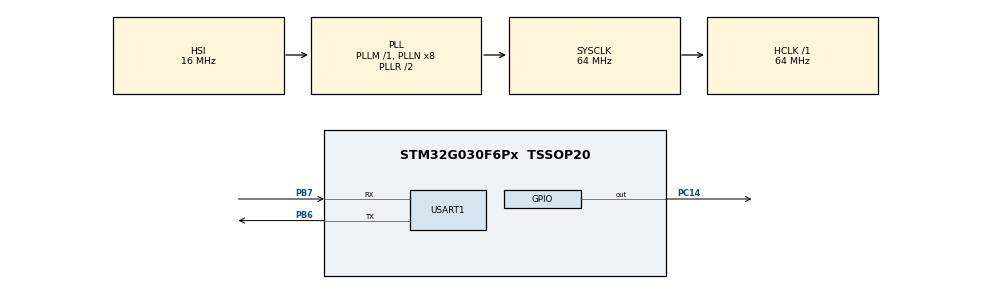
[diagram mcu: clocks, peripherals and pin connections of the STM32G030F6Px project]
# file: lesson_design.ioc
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Dma.Request0=USART1_TX
Dma.Request1=USART1_RX
Dma.USART1_RX.1.Direction=DMA_PERIPH_TO_MEMORY
Dma.USART1_RX.1.EventEnable=DISABLE
Dma.USART1_RX.1.Instance=DMA1_Channel2
Dma.USART1_RX.1.MemDataAlignment=DMA_MDATAALIGN_BYTE
Dma.USART1_RX.1.MemInc=DMA_MINC_ENABLE
Dma.USART1_RX.1.Mode=DMA_NORMAL
Dma.USART1_RX.1.PeriphDataAlignment=DMA_PDATAALIGN_BYTE
Dma.USART1_RX.1.PeriphInc=DMA_PINC_DISABLE
Dma.USART1_RX.1.Polarity=HAL_DMAMUX_REQ_GEN_RISING
Dma.USART1_RX.1.Priority=DMA_PRIORITY_HIGH
Dma.USART1_RX.1.RequestNumber=1
Dma.USART1_RX.1.SignalID=NONE
Dma.USART1_RX.1.SyncEnable=DISABLE
Dma.USART1_RX.1.SyncPolarity=HAL_DMAMUX_SYNC_NO_EVENT
Dma.USART1_RX.1.SyncRequestNumber=1
Dma.USART1_RX.1.SyncSignalID=NONE
Dma.USART1_TX.0.Direction=DMA_MEMORY_TO_PERIPH
Dma.USART1_TX.0.EventEnable=DISABLE
Dma.USART1_TX.0.Instance=DMA1_Channel1
Dma.USART1_TX.0.MemDataAlignment=DMA_MDATAALIGN_BYTE
Dma.USART1_TX.0.MemInc=DMA_MINC_ENABLE
Dma.USART1_TX.0.Mode=DMA_NORMAL
Dma.USART1_TX.0.PeriphDataAlignment=DMA_PDATAALIGN_BYTE
Dma.USART1_TX.0.PeriphInc=DMA_PINC_DISABLE
Dma.USART1_TX.0.Polarity=HAL_DMAMUX_REQ_GEN_RISING
Dma.USART1_TX.0.Priority=DMA_PRIORITY_HIGH
Dma.USART1_TX.0.RequestNumber=1
Dma.USART1_TX.0.SignalID=NONE
Dma.USART1_TX.0.SyncEnable=DISABLE
Dma.USART1_TX.0.SyncPolarity=HAL_DMAMUX_SYNC_NO_EVENT
Dma.USART1_TX.0.SyncRequestNumber=1
Dma.USART1_TX.0.SyncSignalID=NONE
Mcu.Family=STM32G0
Mcu.Name=STM32G030F6Px
Mcu.Package=TSSOP20
NVIC.DMA1_Channel1_IRQn=true\:0\:0\:false\:false\:true\:false\:true\:true
NVIC.DMA1_Channel2_3_IRQn=true\:0\:0\:false\:false\:true\:false\:true\:true
NVIC.USART1_IRQn=true\:0\:0\:false\:false\:true\:false\:true\:true
PA14-BOOT0__PA15.StandardMode=true
PB0__PB1__PB2__PA8.StandardMode=true
PB3__PB4__PB5__PB6.StandardMode=true
PB6.Mode=Asynchronous
PB6.Signal=USART1_TX
PB7.Mode=Asynchronous
PB7.Signal=USART1_RX
PB7__PB8.StandardMode=true
PC14-OSC32_IN\ (PC14).Signal=GPIO_Output
PC14-OSC32_IN\ (PC14)__PB9.StandardMode=true
ProjectManager.HeapSize=0x200
ProjectManager.StackSize=0x400
ProjectManager.TargetToolchain=MDK-ARM V5.32
RCC.ADCFreq_Value=64000000
RCC.AHBFreq_Value=64000000
RCC.CortexFreq_Value=64000000
RCC.EXTERNAL_CLOCK_VALUE=12288000
RCC.HCLKFreq_Value=64000000
RCC.HSE_VALUE=8000000
RCC.HSI_VALUE=16000000
RCC.LSE_VALUE=32768
RCC.SYSCLKFreq_VALUE=64000000
RCC.SYSCLKSource=RCC_SYSCLKSOURCE_PLLCLK
RCC.VCOOutputFreq_Value=128000000
USART1.VirtualMode-Asynchronous=VM_ASYNC
board=custom

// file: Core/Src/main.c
/* USER CODE BEGIN Header */
/**
  ******************************************************************************
  * @file           : main.c
  * @brief          : Main program body
  ******************************************************************************
  * @attention
  *
  * Copyright (c) 2025 STMicroelectronics.
  * All rights reserved.
  *
  * This software is licensed under terms that can be found in the LICENSE file
  * in the root directory of this software component.
  * If no LICENSE file comes with this software, it is provided AS-IS.
  *
  ******************************************************************************
  */
/* USER CODE END Header */
#include "main.h"
#include "dma.h"
#include "usart.h"
#include "gpio.h"

/* USER CODE BEGIN Includes */
#include "stdio.h"
#include "string.h"
#include "stdarg.h"
/* USER CODE END Includes */

void SystemClock_Config(void);

int main(void)
{

  /* MCU Configuration--------------------------------------------------------*/

  /* Reset of all peripherals, Initializes the Flash interface and the Systick. */
  HAL_Init();

  /* Configure the system clock */
  SystemClock_Config();

  /* Initialize all configured peripherals */
  MX_GPIO_Init();
  MX_DMA_Init();
  MX_USART1_UART_Init();

  /* Infinite loop */
  while (1)
  {

    /* USER CODE BEGIN 3 */
	  /*LED测试*/
	  HAL_GPIO_WritePin(GPIOC,GPIO_PIN_14,GPIO_PIN_RESET);
	  HAL_Delay(500);
	  HAL_GPIO_WritePin(GPIOC,GPIO_PIN_14,GPIO_PIN_SET);
	  HAL_Delay(500);

	  /*串口测试*/
	  printf("Hellow World!");
  }
  /* USER CODE END 3 */
}

void SystemClock_Config(void)
{
  RCC_OscInitTypeDef RCC_OscInitStruct = {0};
  RCC_ClkInitTypeDef RCC_ClkInitStruct = {0};

  /** Configure the main internal regulator output voltage
  */
  HAL_PWREx_ControlVoltageScaling(PWR_REGULATOR_VOLTAGE_SCALE1);

  /** Initializes the RCC Oscillators according to the specified parameters
  * in the RCC_OscInitTypeDef structure.
  */
  RCC_OscInitStruct.OscillatorType = RCC_OSCILLATORTYPE_HSI;
  RCC_OscInitStruct.HSIState = RCC_HSI_ON;
  RCC_OscInitStruct.HSIDiv = RCC_HSI_DIV1;
  RCC_OscInitStruct.HSICalibrationValue = RCC_HSICALIBRATION_DEFAULT;
  RCC_OscInitStruct.PLL.PLLState = RCC_PLL_ON;
  RCC_OscInitStruct.PLL.PLLSource = RCC_PLLSOURCE_HSI;
  RCC_OscInitStruct.PLL.PLLM = RCC_PLLM_DIV1;
  RCC_OscInitStruct.PLL.PLLN = 8;
  RCC_OscInitStruct.PLL.PLLP = RCC_PLLP_DIV2;
  RCC_OscInitStruct.PLL.PLLR = RCC_PLLR_DIV2;
  if (HAL_RCC_OscConfig(&RCC_OscInitStruct) != HAL_OK)
  {
    Error_Handler();
  }

  /** Initializes the CPU, AHB and APB buses clocks
  */
  RCC_ClkInitStruct.ClockType = RCC_CLOCKTYPE_HCLK|RCC_CLOCKTYPE_SYSCLK
                              |RCC_CLOCKTYPE_PCLK1;
  RCC_ClkInitStruct.SYSCLKSource = RCC_SYSCLKSOURCE_PLLCLK;
  RCC_ClkInitStruct.AHBCLKDivider = RCC_SYSCLK_DIV1;
  RCC_ClkInitStruct.APB1CLKDivider = RCC_HCLK_DIV1;

  if (HAL_RCC_ClockConfig(&RCC_ClkInitStruct, FLASH_LATENCY_2) != HAL_OK)
  {
    Error_Handler();
  }
}

void Error_Handler(void)
{
  __disable_irq();
  while (1)
  {
  }
}
